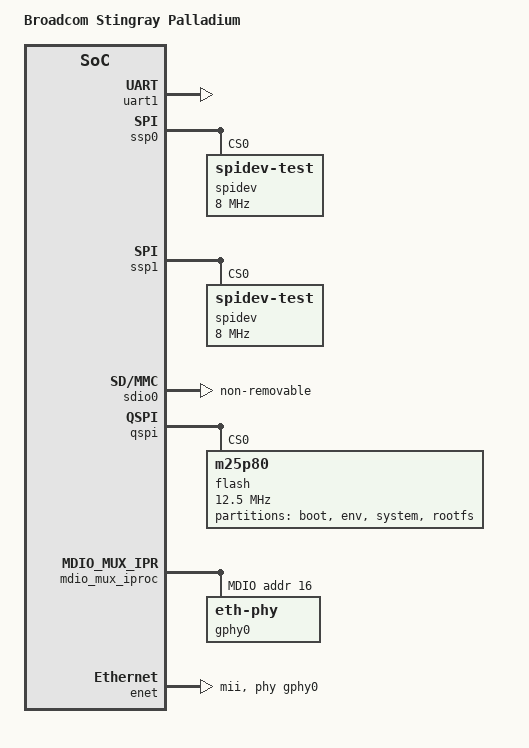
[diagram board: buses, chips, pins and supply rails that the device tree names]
/*
 *  BSD LICENSE
 *
 *  Copyright(c) 2016-2017 Broadcom.  All rights reserved.
 *
 *  Redistribution and use in source and binary forms, with or without
 *  modification, are permitted provided that the following conditions
 *  are met:
 *
 *    * Redistributions of source code must retain the above copyright
 *      notice, this list of conditions and the following disclaimer.
 *    * Redistributions in binary form must reproduce the above copyright
 *      notice, this list of conditions and the following disclaimer in
 *      the documentation and/or other materials provided with the
 *      distribution.
 *    * Neither the name of Broadcom nor the names of its
 *      contributors may be used to endorse or promote products derived
 *      from this software without specific prior written permission.
 *
 *  THIS SOFTWARE IS PROVIDED BY THE COPYRIGHT HOLDERS AND CONTRIBUTORS
 *  "AS IS" AND ANY EXPRESS OR IMPLIED WARRANTIES, INCLUDING, BUT NOT
 *  LIMITED TO, THE IMPLIED WARRANTIES OF MERCHANTABILITY AND FITNESS FOR
 *  A PARTICULAR PURPOSE ARE DISCLAIMED. IN NO EVENT SHALL THE COPYRIGHT
 *  OWNER OR CONTRIBUTORS BE LIABLE FOR ANY DIRECT, INDIRECT, INCIDENTAL,
 *  SPECIAL, EXEMPLARY, OR CONSEQUENTIAL DAMAGES (INCLUDING, BUT NOT
 *  LIMITED TO, PROCUREMENT OF SUBSTITUTE GOODS OR SERVICES; LOSS OF USE,
 *  DATA, OR PROFITS; OR BUSINESS INTERRUPTION) HOWEVER CAUSED AND ON ANY
 *  THEORY OF LIABILITY, WHETHER IN CONTRACT, STRICT LIABILITY, OR TORT
 *  (INCLUDING NEGLIGENCE OR OTHERWISE) ARISING IN ANY WAY OUT OF THE USE
 *  OF THIS SOFTWARE, EVEN IF ADVISED OF THE POSSIBILITY OF SUCH DAMAGE.
 */

/dts-v1/;

#define NUM_CRYPTO	32
#define NUM_RAID	8

/* HACK: Reserve initrd location
 * The memreserve entry for initrd is supposed
 * to be updated in DTB by bootloader before
 * handing over DTB to Linux kernel.
 */
/memreserve/ 0x81000000 0x00800000;

/* HACK: Reserve bl31 location
 * The memreserve entry for bl31 is supposed to
 * be updated in DTB by bootloader before handing
 * over DTB to Linux kernel. This is so because
 * only firmware (or bootloader) know the correct
 * location of bl31 and bl31 location in DDR can
 * also change in-future.
 */
/memreserve/ 0x8f000000 0x00100000;

#include "./stingray-pd-base.dtsi"

/ {
	model = "Broadcom Stingray Palladium";

	chosen { /* HACK: hard-code kernel args and initrd location */
		bootargs = "root=/dev/ram rw console=ttyS0,4800n8 \
			    earlycon=uart8250,mmio32,0x68a10000 cma=64M \
			    maxcpus=2";
		linux,initrd-start = <0x0 0x81000000>;
		linux,initrd-end = <0x0 0x81800000>;
	};
};

&uart1 {
	/* Hack: For palladium we force DLL=1 and DLM=0.
	 * To achieve this, we set:
	 * clock-frequency = <desired_baudrate> x 16
	 */
	clock-frequency = <76800>;
	status = "okay";
};

&ssp0 {
	status = "okay";

	spidev@0 {
		compatible = "spidev-test";
		spi-max-frequency = <8000000>;
		reg = <0>;
	};
};

&ssp1 {
	status = "okay";

	spidev@0 {
		compatible = "spidev-test";
		spi-max-frequency = <8000000>;
		reg = <0>;
	};
};

&sdio0 {
	/* For palladium eMMC is always present. */
	non-removable;
	status = "okay";
};

&qspi {
	bspi-sel = <0>;
	flash: m25p80@0 {
		#address-cells = <1>;
		#size-cells = <1>;
		compatible = "m25p80";
		reg = <0x0>;
		spi-max-frequency = <12500000>;
		m25p,fast-read;
		spi-cpol;
		spi-cpha;

		partition@0 {
			label = "boot";
			reg = <0x00000000 0x100000>;
		};

		partition@1 {
			label = "env";
			reg = <0x000a0000 0x00060000>;
		};

		partition@2 {
			label = "system";
			reg = <0x00100000 0x00600000>;
		};

		partition@3 {
			label = "rootfs";
			reg = <0x00700000 0x01900000>;
		};
	};
};

&mdio_mux_iproc {
	mdio@10 {
		gphy0: eth-phy@10 {
			reg = <0x10>;
		};
	};
};

&enet {
	phy-mode = "mii";
	phy-handle = <&gphy0>;
	/* switch mode used in emulator to bypass phy */
	brcm,enet-switch-mode;
};
